# AVR32SD28 device description
Architecture: AVR8X; Family: AVR
Registers are 8-bit, read-write, reset 0x0 unless marked. A register's access mark holds for its fields unless they carry their own. Offsets are from the block's base; [hi:lo] are bit positions; {n}, {i} and the like mark numbered series; 'fields as' and 'values as' point back to an identical list.

## BOD — Bod interface
Instances: BOD 0x0060
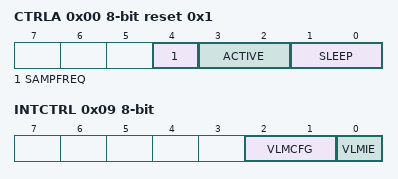
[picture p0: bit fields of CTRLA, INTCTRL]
0x00 CTRLA reset 0x1 — Control A
  [4] SAMPFREQ ro — Sample frequency
    0=128HZ (Sample frequency is 128 Hz); 1=32HZ (Sample frequency is 32 Hz)
  [3:2] ACTIVE ro — Operation in active mode
    0=DISABLE (BOD disabled); 1=ENABLE (BOD enabled in continuous mode); 2=SAMPLE (BOD enabled in sampled mode); 3=ENABLEWAIT (BOD enabled in continuous mode. Execution is halted at wake-up until BOD is running.)
  [1:0] SLEEP — Operation in sleep mode
    0=DISABLE (BOD disabled); 1=ENABLE (BOD enabled in continuous mode); 2=SAMPLE (BOD enabled in sampled mode)
0x01 CTRLB — Control B
  [2:0] LVL ro — Bod level
    0=BODLEVEL0 (1.9V); 1=BODLEVEL1 (2.45V); 2=BODLEVEL2 (2.7V); 3=BODLEVEL3 (2.85V)
0x08 VLMCTRLA — Voltage level monitor Control
  [1:0] VLMLVL — voltage level monitor level
    0=OFF (VLM Disabled); 1=5ABOVE (VLM threshold 5% above BOD level); 2=15ABOVE (VLM threshold 15% above BOD level); 3=25ABOVE (VLM threshold 25% above BOD level)
0x09 INTCTRL — Voltage level monitor interrupt Control
  [2:1] VLMCFG — Configuration
    0=FALLING (VDD falls below VLM threshold); 1=RISING (VDD rises above VLM threshold); 2=BOTH (VDD crosses VLM threshold)
  [0] VLMIE — voltage level monitor interrrupt enable
0x0A INTFLAGS — Voltage level monitor interrupt Flags
  [0] VLMIF — Voltage level monitor interrupt flag
0x0B STATUS — Voltage level monitor status
  [0] VLMS ro
    0=ABOVE (The voltage is above the VLM threshold level); 1=BELOW (The voltage is below the VLM threshold level)

## BOOTROW
Instances: BOOTROW 0x1100
{0x0+i} BOOTROW[{i}] (i=0..255) reset not defined

## CCL — Configurable Custom Logic
Instances: CCL 0x01C0
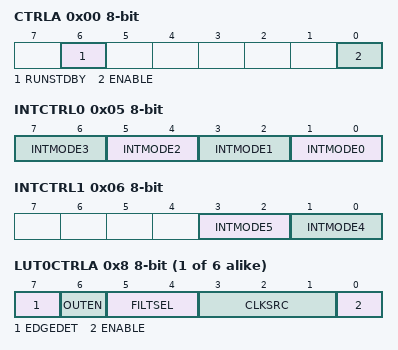
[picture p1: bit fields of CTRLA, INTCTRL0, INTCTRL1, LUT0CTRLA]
0x00 CTRLA — Control Register A
  [6] RUNSTDBY — Run in Standby
  [0] ENABLE
{0x1+i} SEQCTRL{i} (i=0..2) — Sequential Control {i}
  [3:0] SEQSEL — Sequential Selection
    0=DISABLE (Sequential logic disabled); 1=DFF (D FlipFlop); 2=JK (JK FlipFlop); 3=LATCH (D Latch); 4=RS (RS Latch)
0x05 INTCTRL0 — Interrupt Control 0
  [all] fields
    0=INTDISABLE (Interrupt disabled); 1=RISING (Sense rising edge); 2=FALLING (Sense falling edge); 3=BOTH (Sense both edges)
  [2n+1:2n] INTMODE{n} (n=0..3) — Interrupt Mode for LUT{n}
0x06 INTCTRL1 — Interrupt Control 1
  [3:2] INTMODE5 — Interrupt Mode for LUT5
    values as the fields of INTCTRL0
  [1:0] INTMODE4 — Interrupt Mode for LUT4
    values as the fields of INTCTRL0
0x07 INTFLAGS — Interrupt Flags
  [5:0] INT — Interrupt Flag
{0x8+4i} LUT{i}CTRLA (i=0..5) — LUT {i} Control A
  [7] EDGEDET — Edge Detection Enable
    0=DIS (Edge detector is disabled); 1=EN (Edge detector is enabled)
  [6] OUTEN — Output Enable
  [5:4] FILTSEL — Filter Selection
    0=DISABLE (Filter disabled); 1=SYNCH (Synchronizer enabled); 2=FILTER (Filter enabled)
  [3:1] CLKSRC — Clock Source Selection
    0=CLKPER (Peripheral Clock); 1=IN2 (Selection by INSEL2); 4=OSCHF (Internal High-Frequency Oscillator); 5=OSC32K (32.768 kHz oscillator); 6=OSC1K (32.768 kHz oscillator divided by 32)
  [0] ENABLE — LUT Enable
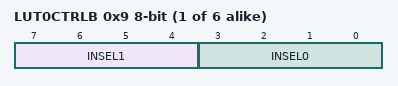
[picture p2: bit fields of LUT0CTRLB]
{0x9+4i} LUT{i}CTRLB (i=0..5) — LUT {i} Control B
  [7:4] INSEL1 — LUT Input 1 Source Selection
    0=MASK (Masked input); 1=FEEDBACK (Feedback input source); 2=LINK (Linked LUT input source); 3=EVENTA (Event input source A); 4=EVENTB (Event input source B); 5=IN1 (IO pin LUTn-IN1 input source); 6=AC1 (AC1 OUT input source); 7=ZCD3 (ZCD3 OUT input source); 8=USART1 (USART1 TXD input source); 9=SPI0 (SPI0 MOSI input source); 10=TCA0 (TCA0 WO1 input source); 11=TCB1 (TCB1 WO input source); 12=TCD0 (TCD0 WOB input source)
  [3:0] INSEL0 — LUT Input 0 Source Selection
    0=MASK (Masked input); 1=FEEDBACK (Feedback input source); 2=LINK (Linked LUT input source); 3=EVENTA (Event input source A); 4=EVENTB (Event input source B); 5=IN0 (IO pin LUTn-IN0 input source); 6=AC0 (AC0 OUT input source); 7=ZCD0 (ZCD0 OUT input source); 8=USART0 (USART0 TXD input source); 9=SPI0 (SPI0 MOSI input source); 10=TCA0 (TCA0 WO0 input source); 11=TCB0 (TCB0 WO input source); 12=TCD0 (TCD0 WOA input source)
{0xA+4i} LUT{i}CTRLC (i=0..5) — LUT {i} Control C
  [3:0] INSEL2 — LUT Input 2 Source Selection
    0=MASK (Masked input); 1=FEEDBACK (Feedback input source); 2=LINK (Linked LUT input source); 3=EVENTA (Event input source A); 4=EVENTB (Event input source B); 5=IN2 (IO pin LUTn-IN2 input source); 6=AC2 (AC2 OUT input source); 7=ZCD3 (ZCD3 OUT input source); 8=USART2 (USART2 TXD input source); 9=SPI0 (SPI0 SCK input source); 10=TCA0 (TCA0 WO2 input source); 11=TCB2 (TCB2 WO input source); 12=TCD0 (TCD0 WOC input source)
{0xB+4i} TRUTH{i} (i=0..5)
  [7:0] TRUTH — Truth Table
